# SAMA7G54D1G device description
Architecture: CORTEX-A7; Family: SAMA; Series: SAMA7G
Registers are 32-bit, read-write, reset 0x0 unless marked. A register's access mark holds for its fields unless they carry their own. Offsets are from the block's base; [hi:lo] are bit positions; {n}, {i} and the like mark numbered series; 'fields as' and 'values as' point back to an identical list; <NAME> marks a mode.

## UDDRC (part 3 of 3) — Enhanced Universal DDR-SDRAM Memory Controller
Instances: DDRUMCTL 0xE3800000
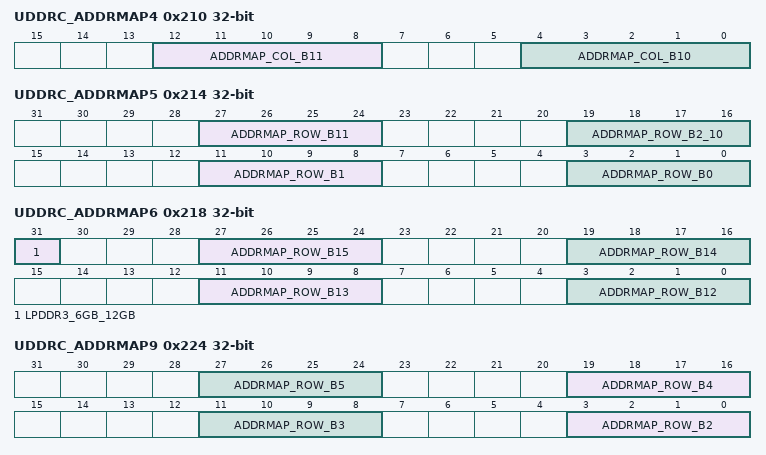
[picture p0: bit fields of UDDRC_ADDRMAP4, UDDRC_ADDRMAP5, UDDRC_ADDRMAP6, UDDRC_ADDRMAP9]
0x210 UDDRC_ADDRMAP4 — Address Map Register 4
  [12:8] ADDRMAP_COL_B11 — - Full bus width mode: Selects the HIF address bit used as column address bit 13 (11 in LPDDR2/LPDDR3 mode). - Half bus width mode: UNUSED. See later in this description for value you need to set to make it unused. - Quarter bus width mode: UNUSED. See later in this description for value you need to set to make it unused. Valid Range: 0 to 7, x, and 31. x indicate a valid value in inline ECC configuration. Internal Base: 11 The selected HIF address bit is determined by adding the internal base to the value of this field. Note: Per JEDEC DDR2/3/mDDR specification, column address bit 10 is reserved for indicating auto-precharge, and hence no source address bit can be mapped to column address bit 10. In LPDDR2/LPDDR3, there is a dedicated bit for auto-precharge in the CA bus and hence column bit 10 is used. In Inline ECC configuration (MEMC_INLINE_ECC=1) and ECC is enabled (ECCCFG0.ecc_mode>0), the highest 3 column address bits must map to the highest 3 valid HIF address bits. If column bit 11 is the highest column address bit, it must map to the highest valid HIF address bit. (x = the highest valid HIF address bit - internal base) If column bit 11 is the second highest column address bit, it must map to the second highest valid HIF address bit. (x = the highest valid HIF address bit - 1 - internal base) If column bit 11 is the third highest column address bit, it must map to the third highest valid HIF address bit. (x = the highest valid HIF address bit - 2 - internal base) If unused, set to 31 and then this column address bit is set to 0. Programming Mode: Static
  [4:0] ADDRMAP_COL_B10 — - Full bus width mode: Selects the HIF address bit used as column address bit 11 (10 in LPDDR2/LPDDR3 mode). - Half bus width mode: Selects the HIF address bit used as column address bit 13 (11 in LPDDR2/LPDDR3 mode). - Quarter bus width mode: UNUSED. See later in this description for value you need to set to make it unused. Valid Range: 0 to 7, x, and 31. x indicate a valid value in inline ECC configuration. Internal Base: 10 The selected HIF address bit is determined by adding the internal base to the value of this field. Note: Per JEDEC DDR2/3/mDDR specification, column address bit 10 is reserved for indicating auto-precharge, and hence no source address bit can be mapped to column address bit 10. In LPDDR2/LPDDR3, there is a dedicated bit for auto-precharge in the CA bus and hence column bit 10 is used. In Inline ECC configuration (MEMC_INLINE_ECC=1) and ECC is enabled (ECCCFG0.ecc_mode>0), the highest 3 column address bits must map to the highest 3 valid HIF address bits. If column bit 10 is the highest column address bit, it must map to the highest valid HIF address bit. (x = the highest valid HIF address bit - internal base) If column bit 10 is the second highest column address bit, it must map to the second highest valid HIF address bit. (x = the highest valid HIF address bit - 1 - internal base) If column bit 10 is the third highest column address bit, it must map to the third highest valid HIF address bit. (x = the highest valid HIF address bit - 2 - internal base) If unused, set to 31 and then this column address bit is set to 0. Programming Mode: Static
0x214 UDDRC_ADDRMAP5 — Address Map Register 5
  [27:24] ADDRMAP_ROW_B11 — Selects the HIF address bit used as row address bit 11. Valid Range: 0 to 11, and 15 Internal Base: 17 The selected HIF address bit is determined by adding the internal base to the value of this field. If unused, set to 15 and then row address bit 11 is set to 0. Programming Mode: Static
  [19:16] ADDRMAP_ROW_B2_10 — Selects the HIF address bits used as row address bits 2 to 10. Valid Range: 0 to 11, and 15 Internal Base: 8 (for row address bit 2), 9 (for row address bit 3), 10 (for row address bit 4) etc increasing to 16 (for row address bit 10) The selected HIF address bit for each of the row address bits is determined by adding the internal base to the value of this field. When set to 15, the values of row address bits 2 to 10 are defined by registers ADDRMAP9, ADDRMAP10, ADDRMAP11. Programming Mode: Static
  [11:8] ADDRMAP_ROW_B1 — Selects the HIF address bits used as row address bit 1. Valid Range: 0 to 11 Internal Base: 7 The selected HIF address bit for each of the row address bits is determined by adding the internal base to the value of this field. Programming Mode: Static
  [3:0] ADDRMAP_ROW_B0 — Selects the HIF address bits used as row address bit 0. Valid Range: 0 to 11 Internal Base: 6 The selected HIF address bit for each of the row address bits is determined by adding the internal base to the value of this field. Programming Mode: Static
0x218 UDDRC_ADDRMAP6 — Address Map Register 6
  [31] LPDDR3_6GB_12GB — Set this to 1 if there is an LPDDR3 SDRAM 6Gb or 12Gb device in use. - 1 - LPDDR3 SDRAM 6Gb/12Gb device in use. Every address having row[14:13]==2'b11 is considered as invalid - 0 - non-LPDDR3 6Gb/12Gb device in use. All addresses are valid Present only in designs configured to support LPDDR3. Programming Mode: Static
  [8n-93:8n-96] ADDRMAP_ROW_B{n} (n=12..15) — Selects the HIF address bit used as row address bit {n}. Valid Range: 0 to 11, and 15 Internal Base: {n+6} The selected HIF address bit is determined by adding the internal base to the value of this field. If unused, set to 15 and then row address bit {n} is set to 0. Programming Mode: Static
0x224 UDDRC_ADDRMAP9 — Address Map Register 9
  [8n-13:8n-16] ADDRMAP_ROW_B{n} (n=2..5) — Selects the HIF address bits used as row address bit {n}. Valid Range: 0 to 11 Internal Base: {n+6} The selected HIF address bit for each of the row address bits is determined by adding the internal base to the value of this field. This register field is used only when ADDRMAP5.addrmap_row_b2_10 is set to value 15. Programming Mode: Static
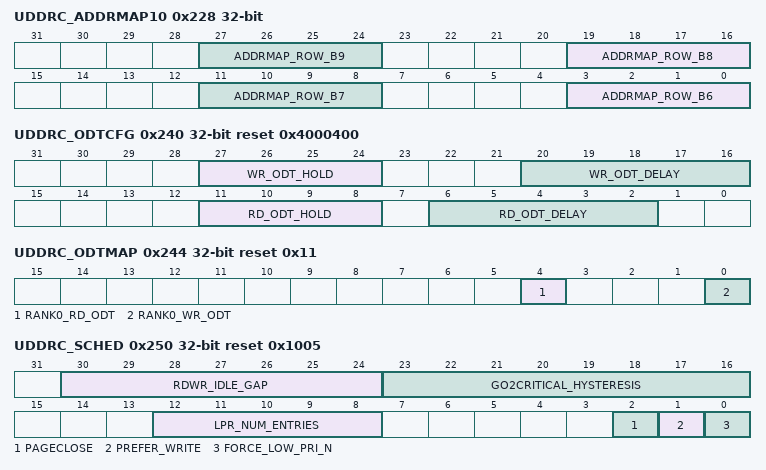
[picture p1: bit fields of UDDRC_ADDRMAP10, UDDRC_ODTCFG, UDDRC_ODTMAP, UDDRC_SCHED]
0x228 UDDRC_ADDRMAP10 — Address Map Register 10
  [8n-45:8n-48] ADDRMAP_ROW_B{n} (n=6..9) — Selects the HIF address bits used as row address bit {n}. Valid Range: 0 to 11 Internal Base: {n+6} The selected HIF address bit for each of the row address bits is determined by adding the internal base to the value of this field. This register field is used only when ADDRMAP5.addrmap_row_b2_10 is set to value 15. Programming Mode: Static
0x22C UDDRC_ADDRMAP11 — Address Map Register 11
  [3:0] ADDRMAP_ROW_B10 — Selects the HIF address bits used as row address bit 10. Valid Range: 0 to 11 Internal Base: 16 The selected HIF address bit for each of the row address bits is determined by adding the internal base to the value of this field. This register field is used only when ADDRMAP5.addrmap_row_b2_10 is set to value 15. Programming Mode: Static
0x240 UDDRC_ODTCFG reset 0x4000400 — ODT Configuration Register
  [27:24] WR_ODT_HOLD — DFI PHY clock cycles to hold ODT for a write command. The minimum supported value is 2. Recommended values: DDR2: - BL8: 0x5 (DDR2-400/533/667), 0x6 (DDR2-800), 0x7 (DDR2-1066) - BL4: 0x3 (DDR2-400/533/667), 0x4 (DDR2-800), 0x5 (DDR2-1066) DDR3: - BL8: 0x6 DDR4: - BL8: 5 + WR_PREAMBLE + CRC_MODE WR_PREAMBLE = 1 (1tCK write preamble), 2 (2tCK write preamble) CRC_MODE = 0 (not CRC mode), 1 (CRC mode) LPDDR3: - BL8: 7 + RU(tODTon(max)/tCK) Unit: DFI PHY clock cycles. Programming Mode: Quasi-dynamic Group 1, Group 4
  [20:16] WR_ODT_DELAY — The delay, in DFI PHY clock cycles, from issuing a write command to setting ODT values associated with that command. ODT setting must remain constant for the entire time that DQS is driven by the uMCTL2. Recommended values: DDR2: - CWL + AL - 3 (DDR2-400/533/667), CWL + AL - 4 (DDR2-800), CWL + AL - 5 (DDR2-1066) If (CWL + AL - 3 < 0), uMCTL2 does not support ODT for write operation. DDR3: - 0x0 DDR4: - DFITMG1.dfi_t_cmd_lat (to adjust for CAL mode) LPDDR3: - WL - 1 - RU(tODTon(max)/tCK)) Unit: DFI PHY clock cycles. Programming Mode: Quasi-dynamic Group 1, Group 4
  [11:8] RD_ODT_HOLD — DFI PHY clock cycles to hold ODT for a read command. The minimum supported value is 2. Recommended values: DDR2: - BL8: 0x6 (not DDR2-1066), 0x7 (DDR2-1066) - BL4: 0x4 (not DDR2-1066), 0x5 (DDR2-1066) DDR3: - BL8 - 0x6 DDR4: - BL8: 5 + RD_PREAMBLE RD_PREAMBLE = 1 (1tCK read preamble), 2 (2tCK read preamble) LPDDR3: - BL8: 5 + RU(tDQSCK(max)/tCK) - RD(tDQSCK(min)/tCK) + RU(tODTon(max)/tCK) Unit: DFI PHY clock cycles. Programming Mode: Quasi-dynamic Group 1, Group 4
  [6:2] RD_ODT_DELAY — The delay, in DFI PHY clock cycles, from issuing a read command to setting ODT values associated with that command. ODT setting must remain constant for the entire time that DQS is driven by the uMCTL2. Recommended values: DDR2: - CL + AL - 4 (not DDR2-1066), CL + AL - 5 (DDR2-1066) If (CL + AL - 4 < 0), uMCTL2 does not support ODT for read operation. DDR3: - CL - CWL DDR4: - CL - CWL - RD_PREAMBLE + WR_PREAMBLE + DFITMG1.dfi_t_cmd_lat (to adjust for CAL mode) WR_PREAMBLE = 1 (1tCK write preamble), 2 (2tCK write preamble) RD_PREAMBLE = 1 (1tCK read preamble), 2 (2tCK read preamble) If (CL - CWL - RD_PREAMBLE + WR_PREAMBLE) < 0, uMCTL2 does not support ODT for read operation. LPDDR3: - RL + RD(tDQSCK(min)/tCK) - 1 - RU(tODTon(max)/tCK) Unit: DFI PHY clock cycles. Programming Mode: Quasi-dynamic Group 1, Group 4
0x244 UDDRC_ODTMAP reset 0x11 — ODT/Rank Map Register
  [4] RANK0_RD_ODT — Indicates which remote ODTs must be turned on during a read from rank 0. Each rank has a remote ODT (in the SDRAM) which can be turned on by setting the appropriate bit here. Rank 0 is controlled by the LSB; rank 1 is controlled by bit next to the LSB, etc. For each rank, set its bit to 1 to enable its ODT. Programming Mode: Static
  [0] RANK0_WR_ODT — Indicates which remote ODTs must be turned on during a write to rank 0. Each rank has a remote ODT (in the SDRAM) which can be turned on by setting the appropriate bit here. Rank 0 is controlled by the LSB; rank 1 is controlled by bit next to the LSB, etc. For each rank, set its bit to 1 to enable its ODT. Programming Mode: Static
0x250 UDDRC_SCHED reset 0x1005 — Scheduler Control Register
  [30:24] RDWR_IDLE_GAP — When the preferred transaction store is empty for these many clock cycles, switch to the alternate transaction store if it is non-empty. The read transaction store (both high and low priority) is the default preferred transaction store and the write transaction store is the alternative store. When prefer write over read is set this is reversed. 0x0 is a legal value for this register. When set to 0x0, the transaction store switching will happen immediately when the switching conditions become true. FOR PERFORMANCE ONLY. Unit: DFI clock cycles. Programming Mode: Static
  [23:16] GO2CRITICAL_HYSTERESIS — UNUSED Programming Mode: Static
  [12:8] LPR_NUM_ENTRIES — Number of entries in the low priority transaction store is this value + 1. (MEMC_NO_OF_ENTRY - (SCHED.lpr_num_entries + 1)) is the number of entries available for the high priority transaction store. Setting this to maximum value allocates all entries to low priority transaction store. Setting this to 0 allocates 1 entry to low priority transaction store and the rest to high priority transaction store. Note: In ECC configurations, the numbers of write and low priority read credits issued is one less than in the non-ECC case. One entry each is reserved in the write and low-priority read CAMs for storing the RMW requests arising out of single bit error correction RMW operation. Programming Mode: Static
  [2] PAGECLOSE — If true, bank is kept open only while there are page hit transactions available in the CAM to that bank. The last read or write command in the CAM with a bank and page hit will be executed with auto-precharge if SCHED1.pageclose_timer=0. Even if this register set to 1 and SCHED1.pageclose_timer is set to 0, explicit precharge (and not auto-precharge) may be issued in some cases where there is a mode switch between Write and Read or between LPR and HPR. The Read and Write commands that are executed as part of the ECC scrub requests are also executed without auto-precharge. If false, the bank remains open until there is a need to close it (to open a different page, or for page timeout or refresh timeout) - also known as open page policy. The open page policy can be overridden by setting the per-command-autopre bit on the HIF interface (hif_cmd_autopre). The pageclose feature provids a midway between Open and Close page policies. FOR PERFORMANCE ONLY. Programming Mode: Quasi-dynamic Group 3
  [1] PREFER_WRITE — If set then the bank selector prefers writes over reads. FOR DEBUG ONLY. Programming Mode: Static
  [0] FORCE_LOW_PRI_N — Active low signal. When asserted ('0'), all incoming transactions are forced to low priority. This implies that all High Priority Read (HPR) and Variable Priority Read commands (VPR) will be treated as Low Priority Read (LPR) commands. On the write side, all Variable Priority Write (VPW) commands will be treated as Normal Priority Write (NPW) commands. Forcing the incoming transactions to low priority implicitly turns off Bypass path for read commands. FOR PERFORMANCE ONLY. Programming Mode: Static
0x254 UDDRC_SCHED1 — Scheduler Control Register 1
  [7:0] PAGECLOSE_TIMER — This field works in conjunction with SCHED.pageclose. It only has meaning if SCHED.pageclose==1. If SCHED.pageclose==1 and pageclose_timer==0, then an auto-precharge may be scheduled for last read or write command in the CAM with a bank and page hit. Note, sometimes an explicit precharge is scheduled instead of the auto-precharge. See SCHED.pageclose for details of when this may happen. If SCHED.pageclose==1 and pageclose_timer>0, then an auto-precharge is not scheduled for last read or write command in the CAM with a bank and page hit. Instead, a timer is started, with pageclose_timer as the initial value. There is a timer on a per bank basis. The timer decrements unless the next read or write in the CAM to a bank is a page hit. It gets reset to pageclose_timer value if the next read or write in the CAM to a bank is a page hit. Once the timer has reached zero, an explcit precharge will be attempted to be scheduled. Unit: DFI clock cycles. Programming Mode: Static
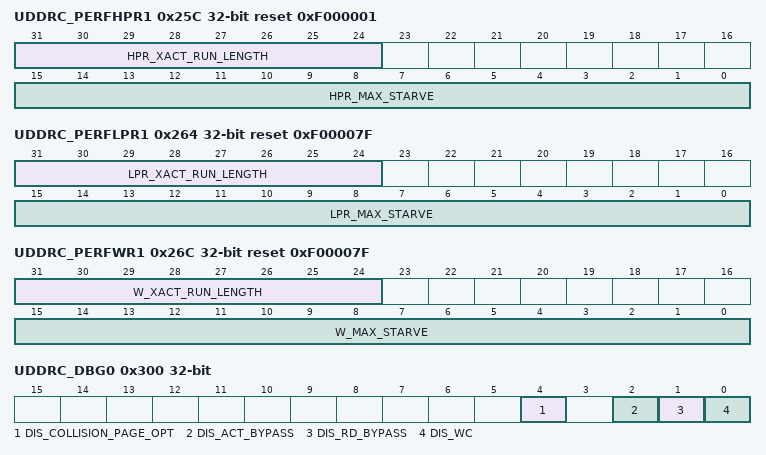
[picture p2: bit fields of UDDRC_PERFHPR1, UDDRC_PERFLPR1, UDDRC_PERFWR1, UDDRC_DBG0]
0x25C UDDRC_PERFHPR1 reset 0xF000001 — High Priority Read CAM Register 1
  [31:24] HPR_XACT_RUN_LENGTH — Number of transactions that are serviced once the HPR queue goes critical is the smaller of: - (a) This number - (b) Number of transactions available. Unit: Transaction. FOR PERFORMANCE ONLY. Programming Mode: Quasi-dynamic Group 3
  [15:0] HPR_MAX_STARVE — Number of DFI clocks that the HPR queue can be starved before it goes critical. The minimum valid functional value for this register is 0x1. Programming it to 0x0 will disable the starvation functionality; during normal operation, this function should not be disabled as it will cause excessive latencies. FOR PERFORMANCE ONLY. Unit: DFI clock cycles. Programming Mode: Quasi-dynamic Group 3
0x264 UDDRC_PERFLPR1 reset 0xF00007F — Low Priority Read CAM Register 1
  [31:24] LPR_XACT_RUN_LENGTH — Number of transactions that are serviced once the LPR queue goes critical is the smaller of: - (a) This number - (b) Number of transactions available. Unit: Transaction. FOR PERFORMANCE ONLY. Programming Mode: Quasi-dynamic Group 3
  [15:0] LPR_MAX_STARVE — Number of DFI clocks that the LPR queue can be starved before it goes critical. The minimum valid functional value for this register is 0x1. Programming it to 0x0 will disable the starvation functionality; during normal operation, this function should not be disabled as it will cause excessive latencies. FOR PERFORMANCE ONLY. Unit: DFI clock cycles. Programming Mode: Quasi-dynamic Group 3
0x26C UDDRC_PERFWR1 reset 0xF00007F — Write CAM Register 1
  [31:24] W_XACT_RUN_LENGTH — Number of transactions that are serviced once the WR queue goes critical is the smaller of: - (a) This number - (b) Number of transactions available. Unit: Transaction. FOR PERFORMANCE ONLY. Programming Mode: Quasi-dynamic Group 3
  [15:0] W_MAX_STARVE — Number of DFI clocks that the WR queue can be starved before it goes critical. The minimum valid functional value for this register is 0x1. Programming it to 0x0 will disable the starvation functionality; during normal operation, this function should not be disabled as it will cause excessive latencies. FOR PERFORMANCE ONLY. Unit: DFI clock cycles. Programming Mode: Quasi-dynamic Group 3
0x300 UDDRC_DBG0 — Debug Register 0
  [4] DIS_COLLISION_PAGE_OPT — When this is set to '0', auto-precharge is disabled for the flushed command in a collision case. Collision cases are write followed by read to same address, read followed by write to same address, or write followed by write to same address with DBG0.dis_wc bit = 1 (where same address comparisons exclude the two address bits representing critical word). FOR DEBUG ONLY. Programming Mode: Static
  [2] DIS_ACT_BYPASS — Only present in designs supporting activate bypass. When 1, disable bypass path for high priority read activates FOR DEBUG ONLY. Programming Mode: Static
  [1] DIS_RD_BYPASS — Only present in designs supporting read bypass. When 1, disable bypass path for high priority read page hits FOR DEBUG ONLY. Programming Mode: Static
  [0] DIS_WC — When 1, disable write combine. FOR DEBUG ONLY Programming Mode: Static
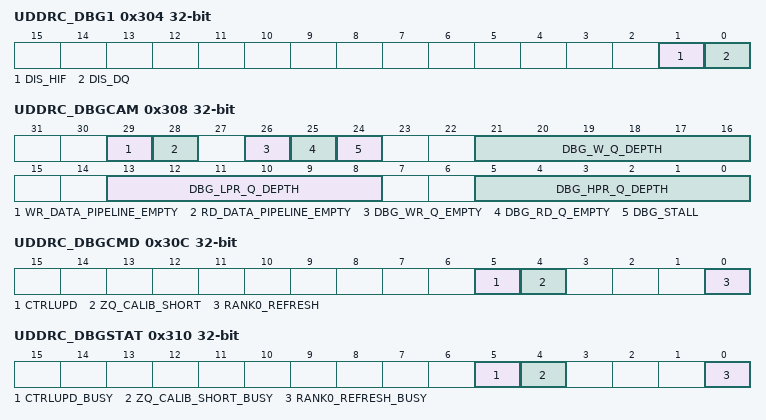
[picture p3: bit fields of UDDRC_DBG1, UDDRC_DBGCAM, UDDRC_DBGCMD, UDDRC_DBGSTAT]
0x304 UDDRC_DBG1 — Debug Register 1
  [1] DIS_HIF — When 1, uMCTL2 asserts the HIF command signal hif_cmd_stall. uMCTL2 will ignore the hif_cmd_valid and all other associated request signals. This bit is intended to be switched on-the-fly. Programming Mode: Dynamic
  [0] DIS_DQ — When 1, uMCTL2 will not de-queue any transactions from the CAM. Bypass is also disabled. All transactions are queued in the CAM. No reads or writes are issued to SDRAM as long as this is asserted. This bit may be used to prevent reads or writes being issued by the uMCTL2, which makes it safe to modify certain register fields associated with reads and writes (see User Guide for details). After setting this bit, it is strongly recommended to poll DBGCAM.wr_data_pipeline_empty and DBGCAM.rd_data_pipeline_empty, before making changes to any registers which affect reads and writes. This will ensure that the relevant logic in the DDRC is idle. This bit is intended to be switched on-the-fly. Programming Mode: Dynamic
0x308 UDDRC_DBGCAM ro — CAM Debug Register
  [29] WR_DATA_PIPELINE_EMPTY — This bit indicates that the write data pipeline on the DFI interface is empty. This register is intended to be polled at least twice after setting DBG1.dis_dq, to ensure that all remaining commands/data have completed. Programming Mode: Dynamic
  [28] RD_DATA_PIPELINE_EMPTY — This bit indicates that the read data pipeline on the DFI interface is empty. This register is intended to be polled at least twice after setting DBG1.dis_dq, to ensure that all remaining commands/data have completed. Programming Mode: Dynamic
  [26] DBG_WR_Q_EMPTY — When 1, all the Write command queues and Write data buffers inside DDRC are empty. This register is to be used for debug purpose. An example use-case scenario: When Controller enters Self-Refresh using the Low-Power entry sequence, Controller is expected to have executed all the commands in its queues and the write and read data drained. Hence this register should be 1 at that time. FOR DEBUG ONLY Programming Mode: Dynamic
  [25] DBG_RD_Q_EMPTY — When 1, all the Read command queues and Read data buffers inside DDRC are empty. This register is to be used for debug purpose. An example use-case scenario: When Controller enters Self-Refresh using the Low-Power entry sequence, Controller is expected to have executed all the commands in its queues and the write and read data drained. Hence this register should be 1 at that time. FOR DEBUG ONLY Programming Mode: Dynamic
  [24] DBG_STALL — Stall FOR DEBUG ONLY Programming Mode: Dynamic
  [21:16] DBG_W_Q_DEPTH — Write queue depth The last entry of WR queue is reserved for ECC SCRUB operation. This entry is not included in the calculation of the queue depth. FOR DEBUG ONLY Programming Mode: Dynamic
  [13:8] DBG_LPR_Q_DEPTH — Low priority read queue depth The last entry of Lpr queue is reserved for ECC SCRUB operation. This entry is not included in the calculation of the queue depth. FOR DEBUG ONLY Programming Mode: Dynamic
  [5:0] DBG_HPR_Q_DEPTH — High priority read queue depth FOR DEBUG ONLY Programming Mode: Dynamic
0x30C UDDRC_DBGCMD — Command Debug Register
  [5] CTRLUPD — Setting this register bit to 1 indicates to the uMCTL2 to issue a dfi_ctrlupd_req to the PHY. When this request is stored in the uMCTL2, the bit is automatically cleared. This operation must only be performed when DFIUPD0.dis_auto_ctrlupd=1. Programming Mode: Dynamic
  [4] ZQ_CALIB_SHORT — Setting this register bit to 1 indicates to the uMCTL2 to issue a ZQCS (ZQ calibration short)/MPC(ZQ calibration) command to the SDRAM. When this request is stored in the uMCTL2, the bit is automatically cleared. This operation can be performed only when ZQCTL0.dis_auto_zq=1. It is recommended NOT to set this register bit if in Init, in Self-Refresh(except LPDDR4) or SR-Powerdown(LPDDR4) or Deep power-down operating modes or Maximum Power Saving Mode. For Self-Refresh(except LPDDR4) or SR-Powerdown(LPDDR4) it will be scheduled after SR(except LPDDR4) or SPRD(LPDDR4) has been exited. For Deep power down and Maximum Power Saving Mode, it will not be scheduled, although DBGSTAT.zq_calib_short_busy will be de-asserted. Programming Mode: Dynamic
  [0] RANK0_REFRESH — Setting this register bit to 1 indicates to the uMCTL2 to issue a refresh to rank 0. Writing to this bit causes DBGSTAT.rank0_refresh_busy to be set. When DBGSTAT.rank0_refresh_busy is cleared, the command has been stored in uMCTL2. For 3DS configuration, refresh is sent to rank index 0. This operation can be performed only when RFSHCTL3.dis_auto_refresh=1. It is recommended NOT to set this register bit if in Init or Deep power-down operating modes or Maximum Power Saving Mode. Programming Mode: Dynamic
0x310 UDDRC_DBGSTAT ro — Status Debug Register
  [5] CTRLUPD_BUSY — SoC core may initiate a ctrlupd operation only if this signal is low. This signal goes high in the clock after the uMCTL2 accepts the ctrlupd request. It goes low when the ctrlupd operation is initiated in the uMCTL2. It is recommended not to perform ctrlupd operations when this signal is high. - 0 - Indicates that the SoC core can initiate a ctrlupd operation - 1 - Indicates that ctrlupd operation has not been initiated yet in the uMCTL2 Programming Mode: Dynamic
  [4] ZQ_CALIB_SHORT_BUSY — SoC core may initiate a ZQCS (ZQ calibration short) operation only if this signal is low. This signal goes high in the clock after the uMCTL2 accepts the ZQCS request. It goes low when the ZQCS operation is initiated in the uMCTL2. It is recommended not to perform ZQCS operations when this signal is high. - 0 - Indicates that the SoC core can initiate a ZQCS operation - 1 - Indicates that ZQCS operation has not been initiated yet in the uMCTL2 Programming Mode: Dynamic
  [0] RANK0_REFRESH_BUSY — SoC core may initiate a rank0_refresh operation (refresh operation to rank 0) only if this signal is low. This signal goes high in the clock after DBGCMD.rank0_refresh is set to one. It goes low when the rank0_refresh operation is stored in the uMCTL2. It is recommended not to perform rank0_refresh operations when this signal is high. - 0 - Indicates that the SoC core can initiate a rank0_refresh operation - 1 - Indicates that rank0_refresh operation has not been stored yet in the uMCTL2 Programming Mode: Dynamic
0x320 UDDRC_SWCTL reset 0x1 — Software Register Programming Control Enable
  [0] SW_DONE — Enable quasi-dynamic register programming outside reset. Program register to 0 to enable quasi-dynamic programming. Set back register to 1 once programming is done. Programming Mode: Dynamic
0x324 UDDRC_SWSTAT ro reset 0x1 — Software Register Programming Control Status
  [0] SW_DONE_ACK — Register programming done. This register is the echo of SWCTL.sw_done. Wait for sw_done value 1 to propagate to sw_done_ack at the end of the programming sequence to ensure that the correct registers values are propagated to the destination clock domains. Programming Mode: Static
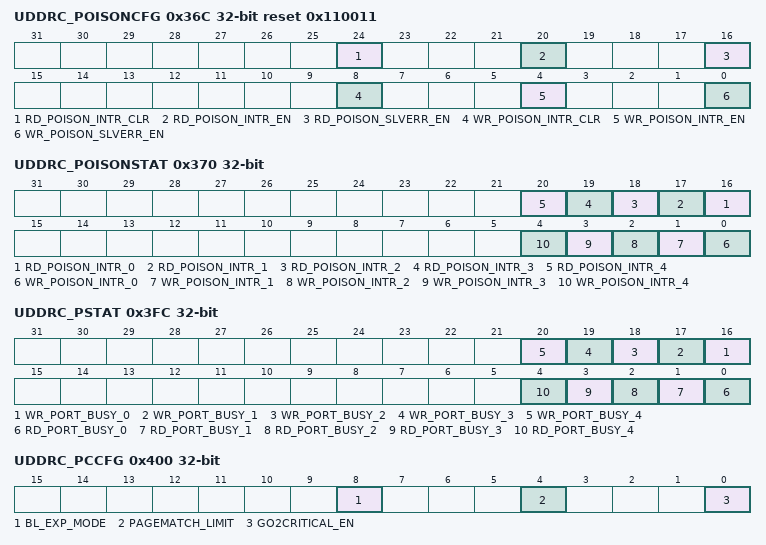
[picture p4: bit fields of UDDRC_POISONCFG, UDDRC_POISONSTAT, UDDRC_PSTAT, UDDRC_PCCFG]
0x36C UDDRC_POISONCFG reset 0x110011 — AXI Poison Configuration Register. Common for all AXI ports
  [24] RD_POISON_INTR_CLR — Interrupt clear for read transaction poisoning. Allow 2/3 clock cycles for correct value to propagate to core logic and clear the interrupts. uMCTL2 automatically clears this bit. Programming Mode: Dynamic
  [20] RD_POISON_INTR_EN — If set to 1, enables interrupts for read transaction poisoning Programming Mode: Dynamic
  [16] RD_POISON_SLVERR_EN — If set to 1, enables SLVERR response for read transaction poisoning Programming Mode: Dynamic
  [8] WR_POISON_INTR_CLR — Interrupt clear for write transaction poisoning. Allow 2/3 clock cycles for correct value to propagate to core logic and clear the interrupts. uMCTL2 automatically clears this bit. Programming Mode: Dynamic
  [4] WR_POISON_INTR_EN — If set to 1, enables interrupts for write transaction poisoning Programming Mode: Dynamic
  [0] WR_POISON_SLVERR_EN — If set to 1, enables SLVERR response for write transaction poisoning Programming Mode: Dynamic
0x370 UDDRC_POISONSTAT ro — AXI Poison Status Register
  [n+16] RD_POISON_INTR_{n} (n=0..4) — Read transaction poisoning error interrupt for port {n}. This register is a APB clock copy (double register synchronizer) of the interrupt asserted when a transaction is poisoned on the corresponding AXI port's read address channel. Bit 0 corresponds to Port 0, and so on. Interrupt is cleared by register rd_poison_intr_clr, then value propagated to APB clock. Programming Mode: Dynamic
  [n] WR_POISON_INTR_{n} (n=0..4) — Write transaction poisoning error interrupt for port {n}. This register is a APB clock copy (double register synchronizer) of the interrupt asserted when a transaction is poisoned on the corresponding AXI port's write address channel. Bit 0 corresponds to Port 0, and so on. Interrupt is cleared by register wr_poison_intr_clr, then value propagated to APB clock. Programming Mode: Dynamic
0x3F0 UDDRC_DERATESTAT ro — Temperature Derate Status Register
  [0] DERATE_TEMP_LIMIT_INTR — Derate temperature interrupt indicating LPDDR2/3/4 SDRAM temperature operating limit is exceeded. This register field is set to 1 when the value read from MR4[2:0] is 3'b000 or 3'b111. Cleared by register DERATECTL.derate_temp_limit_intr_clr. Programming Mode: Static
0x3FC UDDRC_PSTAT ro — Port Status Register
  [n+16] WR_PORT_BUSY_{n} (n=0..4) — Indicates if there are outstanding writes for AXI port {n}. Programming Mode: Dynamic
  [n] RD_PORT_BUSY_{n} (n=0..4) — Indicates if there are outstanding reads for AXI port {n}. Programming Mode: Dynamic
0x400 UDDRC_PCCFG — Port Common Configuration Register
  [8] BL_EXP_MODE — Burst length expansion mode. By default (i.e. bl_exp_mode==0) XPI expands every AXI burst into multiple HIF commands, using the memory burst length as a unit. If set to 1, then XPI will use half of the memory burst length as a unit. This applies to both reads and writes. When MSTR.data_bus_width==00, setting bl_exp_mode to 1 has no effect. This can be used in cases where Partial Writes is enabled (UMCTL2_PARTIAL_WR=1), in order to avoid or minimize t_ccd_l penalty in DDR4 and t_ccd_mw penalty in LPDDR4. Hence, bl_exp_mode=1 is only recommended if DDR4 or LPDDR4. Note that if DBICTL.dm_en=0, functionality is not supported in the following cases: - UMCTL2_PARTIAL_WR=0 - UMCTL2_PARTIAL_WR=1, MSTR.data_bus_width=01, MEMC_BURST_LENGTH=8 and MSTR.burst_rdwr=1000 (LPDDR4 only) - UMCTL2_PARTIAL_WR=1, MSTR.data_bus_width=01, MEMC_BURST_LENGTH=4 and MSTR.burst_rdwr=0100 (DDR4 only), with either MSTR.burstchop=0 or CRCPARCTL1.crc_enable=1 Functionality is also not supported if Data Channel Interleave is enabled Programming Mode: Static
  [4] PAGEMATCH_LIMIT — Page match four limit. If set to 1, limits the number of consecutive same page DDRC transactions that can be granted by the Port Arbiter to four when Page Match feature is enabled. If set to 0, there is no limit imposed on number of consecutive same page DDRC transactions. Programming Mode: Static
  [0] GO2CRITICAL_EN — If set to 1 (enabled), sets co_gs_go2critical_wr and co_gs_go2critical_lpr/co_gs_go2critical_hpr signals going to DDRC based on urgent input (awurgent, arurgent) coming from AXI master. If set to 0 (disabled), co_gs_go2critical_wr and co_gs_go2critical_lpr/co_gs_go2critical_hpr signals at DDRC are driven to 1b'0. For uPCTL2, this register field must be set to 0 Programming Mode: Static
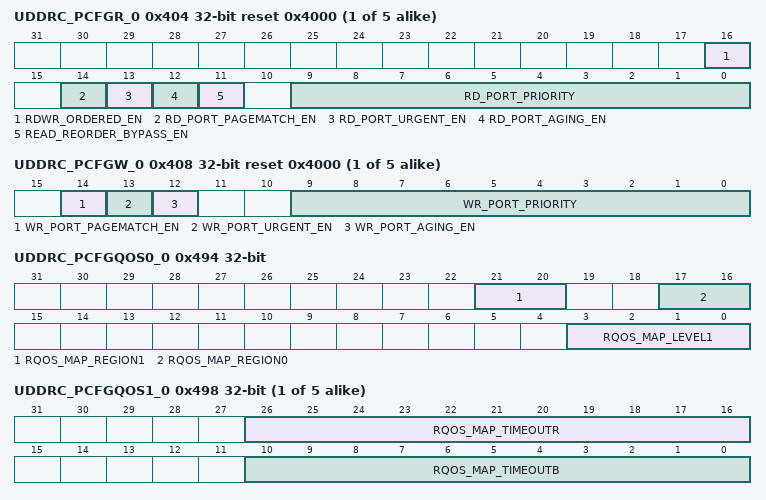
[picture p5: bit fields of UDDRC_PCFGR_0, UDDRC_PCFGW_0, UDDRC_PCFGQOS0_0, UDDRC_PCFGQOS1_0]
{0x404+0xB0*i} UDDRC_PCFGR_{i} reset 0x4000 (i=0..4) — Port n Configuration Read Register
  [16] RDWR_ORDERED_EN — Read/Write AXI transactions acceptance ordering to the same address on a giben port will not be respected when transported to the DFI
  [14] RD_PORT_PAGEMATCH_EN — If set to 1, enables the Page Match feature. If enabled, once a requesting port is granted, the port is continued to be granted if the following immediate commands are to the same memory page (same bank and same row). See also related PCCFG.pagematch_limit register. Programming Mode: Static
  [13] RD_PORT_URGENT_EN — If set to 1, enables the AXI urgent sideband signal (arurgent). When enabled and arurgent is asserted by the master, that port becomes the highest priority and co_gs_go2critical_lpr/co_gs_go2critical_hpr signal to DDRC is asserted if enabled in PCCFG.go2critical_en register. Note that arurgent signal can be asserted anytime and as long as required which is independent of address handshaking (it is not associated with any particular command). Programming Mode: Static
  [12] RD_PORT_AGING_EN — If set to 1, enables aging function for the read channel of the port. Programming Mode: Static
  [11] READ_REORDER_BYPASS_EN — All transactions can be reordered even if ID not found in any RBB channel
  [9:0] RD_PORT_PRIORITY — Determines the initial load value of read aging counters. These counters will be parallel loaded after reset, or after each grant to the corresponding port. The aging counters down-count every clock cycle where the port is requesting but not granted. The higher significant 5-bits of the read aging counter sets the priority of the read channel of a given port. Port's priority will increase as the higher significant 5-bits of the counter starts to decrease. When the aging counter becomes 0, the corresponding port channel will have the highest priority level (timeout condition - Priority0). For multi-port configurations, the aging counters cannot be used to set port priorities when external dynamic priority inputs (arqos) are enabled (timeout is still applicable). For single port configurations, the aging counters are only used when they timeout (become 0) to force read-write direction switching. In this case, external dynamic priority input, arqos (for reads only) can still be used to set the DDRC read priority (2 priority levels: low priority read - LPR, high priority read - HPR) on a command by command basis. Note: The two LSBs of this register field are tied internally to 2'b00. Programming Mode: Static
{0x408+0xB0*i} UDDRC_PCFGW_{i} reset 0x4000 (i=0..4) — Port n Configuration Write Register
  [14] WR_PORT_PAGEMATCH_EN — If set to 1, enables the Page Match feature. If enabled, once a requesting port is granted, the port is continued to be granted if the following immediate commands are to the same memory page (same bank and same row). See also related PCCFG.pagematch_limit register. Programming Mode: Static
  [13] WR_PORT_URGENT_EN — If set to 1, enables the AXI urgent sideband signal (awurgent). When enabled and awurgent is asserted by the master, that port becomes the highest priority and co_gs_go2critical_wr signal to DDRC is asserted if enabled in PCCFG.go2critical_en register. Note that awurgent signal can be asserted anytime and as long as required which is independent of address handshaking (it is not associated with any particular command). Programming Mode: Static
  [12] WR_PORT_AGING_EN — If set to 1, enables aging function for the write channel of the port. Programming Mode: Static
  [9:0] WR_PORT_PRIORITY — Determines the initial load value of write aging counters. These counters will be parallel loaded after reset, or after each grant to the corresponding port. The aging counters down-count every clock cycle where the port is requesting but not granted. The higher significant 5-bits of the write aging counter sets the initial priority of the write channel of a given port. Port's priority will increase as the higher significant 5-bits of the counter starts to decrease. When the aging counter becomes 0, the corresponding port channel will have the highest priority level. For multi-port configurations, the aging counters cannot be used to set port priorities when external dynamic priority inputs (awqos) are enabled (timeout is still applicable). For single port configurations, the aging counters are only used when they timeout (become 0) to force read-write direction switching. Note: The two LSBs of this register field are tied internally to 2'b00. Programming Mode: Static
{0x490+0xB0*i} UDDRC_PCTRL_{i} (i=0..4) — Port n Control Register
  [0] PORT_EN — Enables AXI port n. Programming Mode: Dynamic
0x494 UDDRC_PCFGQOS0_0 — Port n Read QoS Configuration Register 0
  [21:20] RQOS_MAP_REGION1 — This bitfield indicates the traffic class of region 1. Valid values are: - 0 : LPR - 1: VPR - 2: HPR For dual address queue configurations, region1 maps to the blue address queue. In this case, valid values are - 0: LPR - 1: VPR only When VPR support is disabled (UMCTL2_VPR_EN = 0) and traffic class of region 1 is set to 1 (VPR), VPR traffic is aliased to LPR traffic. Programming Mode: Quasi-dynamic Group 3
  [17:16] RQOS_MAP_REGION0 — This bitfield indicates the traffic class of region 0. Valid values are: - 0: LPR - 1: VPR - 2: HPR For dual address queue configurations, region 0 maps to the blue address queue. In this case, valid values are: 0: LPR and 1: VPR only. When VPR support is disabled (UMCTL2_VPR_EN = 0) and traffic class of region0 is set to 1 (VPR), VPR traffic is aliased to LPR traffic. Programming Mode: Quasi-dynamic Group 3
  [3:0] RQOS_MAP_LEVEL1 — Separation level1 indicating the end of region0 mapping; start of region0 is 0. Possible values for level1 are 0 to 13 (for dual RAQ) or 0 to 14 (for single RAQ) which corresponds to arqos. Note that for PA, arqos values are used directly as port priorities, where the higher the value corresponds to higher port priority. All of the map_level* registers must be set to distinct values. Programming Mode: Quasi-dynamic Group 3
{0x498+0xB0*i} UDDRC_PCFGQOS1_{i} (i=0..4) — Port n Read QoS Configuration Register 1
  [26:16] RQOS_MAP_TIMEOUTR — Specifies the timeout value for transactions mapped to the red address queue. Programming Mode: Quasi-dynamic Group 3
  [10:0] RQOS_MAP_TIMEOUTB — Specifies the timeout value for transactions mapped to the blue address queue. Programming Mode: Quasi-dynamic Group 3
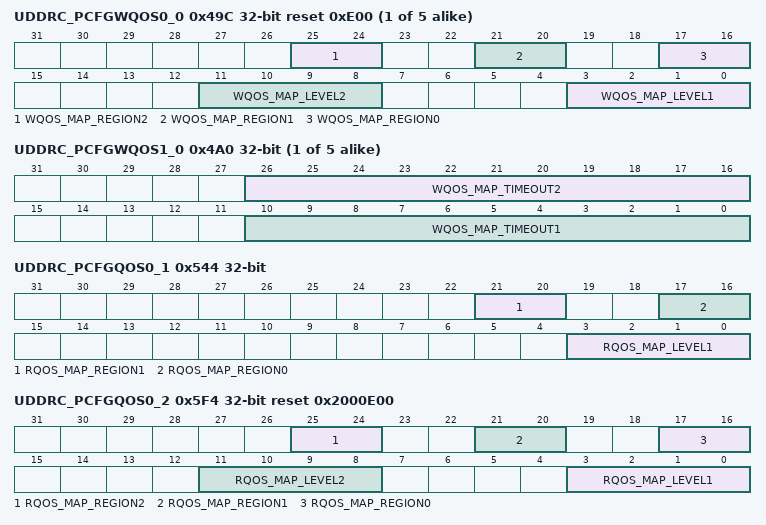
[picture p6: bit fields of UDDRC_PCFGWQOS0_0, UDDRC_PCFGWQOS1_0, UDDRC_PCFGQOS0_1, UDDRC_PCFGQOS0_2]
{0x49C+0xB0*i} UDDRC_PCFGWQOS0_{i} reset 0xE00 (i=0..4) — Port n Write QoS Configuration Register 0
  [25:24] WQOS_MAP_REGION2 — This bitfield indicates the traffic class of region 2. Valid values are: 0: NPW, 1: VPW. When VPW support is disabled (UMCTL2_VPW_EN = 0) and traffic class of region 2 is set to 1 (VPW), VPW traffic is aliased to NPW traffic. Programming Mode: Quasi-dynamic Group 3
  [21:20] WQOS_MAP_REGION1 — This bitfield indicates the traffic class of region 1. Valid values are: 0: NPW, 1: VPW. When VPW support is disabled (UMCTL2_VPW_EN = 0) and traffic class of region 1 is set to 1 (VPW), VPW traffic is aliased to NPW traffic. Programming Mode: Quasi-dynamic Group 3
  [17:16] WQOS_MAP_REGION0 — This bitfield indicates the traffic class of region 0. Valid values are: 0: NPW, 1: VPW. When VPW support is disabled (UMCTL2_VPW_EN = 0) and traffic class of region 0 is set to 1 (VPW), VPW traffic is aliased to NPW traffic. Programming Mode: Quasi-dynamic Group 3
  [11:8] WQOS_MAP_LEVEL2 — Separation level2 indicating the end of region1 mapping; start of region1 is (level1 + 1). Possible values for level2 are (level1 + 1) to 14 which corresponds to awqos. Region2 starts from (level2 + 1) up to 15. Note that for PA, awqos values are used directly as port priorities, where the higher the value corresponds to higher port priority. All of the map_level* registers must be set to distinct values. Programming Mode: Quasi-dynamic Group 3
  [3:0] WQOS_MAP_LEVEL1 — Separation level indicating the end of region0 mapping; start of region0 is 0. Possible values for level1 are 0 to 13 which corresponds to awqos. Note that for PA, awqos values are used directly as port priorities, where the higher the value corresponds to higher port priority. All of the map_level* registers must be set to distinct values. Programming Mode: Quasi-dynamic Group 3
{0x4A0+0xB0*i} UDDRC_PCFGWQOS1_{i} (i=0..4) — Port n Write QoS Configuration Register 1
  [26:16] WQOS_MAP_TIMEOUT2 — Specifies the timeout value for write transactions in region 2. Programming Mode: Quasi-dynamic Group 3
  [10:0] WQOS_MAP_TIMEOUT1 — Specifies the timeout value for write transactions in region 0 and 1. Programming Mode: Quasi-dynamic Group 3
0x544 UDDRC_PCFGQOS0_1 — Port n Read QoS Configuration Register 0
  fields as UDDRC_PCFGQOS0_0
0x5F4 UDDRC_PCFGQOS0_2 reset 0x2000E00 — Port n Read QoS Configuration Register 0
  [25:24] RQOS_MAP_REGION2 — This bitfield indicates the traffic class of region2. For dual address queue configurations, region2 maps to the red address queue. Valid values are 1: VPR and 2: HPR only. When VPR support is disabled (UMCTL2_VPR_EN = 0) and traffic class of region2 is set to 1 (VPR), VPR traffic is aliased to LPR traffic. Programming Mode: Quasi-dynamic Group 3
  [21:20] RQOS_MAP_REGION1 — This bitfield indicates the traffic class of region 1. Valid values are: - 0 : LPR - 1: VPR - 2: HPR For dual address queue configurations, region1 maps to the blue address queue. In this case, valid values are - 0: LPR - 1: VPR only When VPR support is disabled (UMCTL2_VPR_EN = 0) and traffic class of region 1 is set to 1 (VPR), VPR traffic is aliased to LPR traffic. Programming Mode: Quasi-dynamic Group 3
  [17:16] RQOS_MAP_REGION0 — This bitfield indicates the traffic class of region 0. Valid values are: - 0: LPR - 1: VPR - 2: HPR For dual address queue configurations, region 0 maps to the blue address queue. In this case, valid values are: 0: LPR and 1: VPR only. When VPR support is disabled (UMCTL2_VPR_EN = 0) and traffic class of region0 is set to 1 (VPR), VPR traffic is aliased to LPR traffic. Programming Mode: Quasi-dynamic Group 3
  [11:8] RQOS_MAP_LEVEL2 — Separation level2 indicating the end of region1 mapping; start of region1 is (level1 + 1). Possible values for level2 are (level1 + 1) to 14 which corresponds to arqos. Region2 starts from (level2 + 1) up to 15. Note that for PA, arqos values are used directly as port priorities, where the higher the value corresponds to higher port priority. All of the map_level* registers must be set to distinct values. Programming Mode: Quasi-dynamic Group 3
  [3:0] RQOS_MAP_LEVEL1 — Separation level1 indicating the end of region0 mapping; start of region0 is 0. Possible values for level1 are 0 to 13 (for dual RAQ) or 0 to 14 (for single RAQ) which corresponds to arqos. Note that for PA, arqos values are used directly as port priorities, where the higher the value corresponds to higher port priority. All of the map_level* registers must be set to distinct values. Programming Mode: Quasi-dynamic Group 3
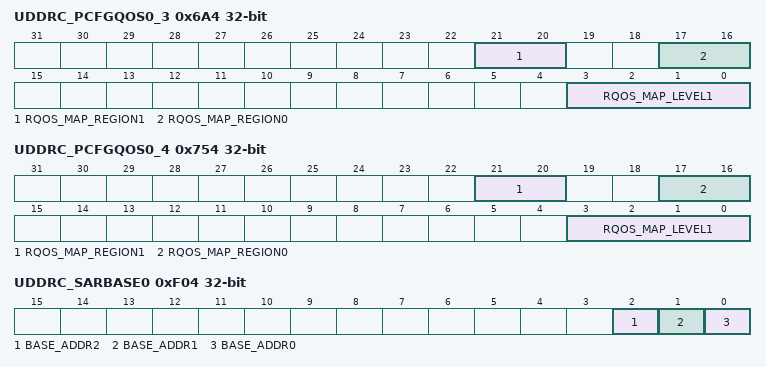
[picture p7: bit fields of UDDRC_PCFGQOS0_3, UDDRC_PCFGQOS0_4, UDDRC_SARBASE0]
0x6A4 UDDRC_PCFGQOS0_3 — Port n Read QoS Configuration Register 0
  fields as UDDRC_PCFGQOS0_0
0x754 UDDRC_PCFGQOS0_4 — Port n Read QoS Configuration Register 0
  fields as UDDRC_PCFGQOS0_0
0xF04 UDDRC_SARBASE0 — SAR Base Address Register n
  [2] BASE_ADDR2 — Base address for address region n specified as awaddr[UMCTL2_A_ADDRW-1:x] and araddr[UMCTL2_A_ADDRW-1:x] where 2 is determined by the minimum block size parameter UMCTL2_SARMINSIZE: (x=log2(block size)). Programming Mode: Static
  [1] BASE_ADDR1 — Base address for address region n specified as awaddr[UMCTL2_A_ADDRW-1:x] and araddr[UMCTL2_A_ADDRW-1:x] where 1 is determined by the minimum block size parameter UMCTL2_SARMINSIZE: (x=log2(block size)). Programming Mode: Static
  [0] BASE_ADDR0 — Base address for address region n specified as awaddr[UMCTL2_A_ADDRW-1:x] and araddr[UMCTL2_A_ADDRW-1:x] where 0 is determined by the minimum block size parameter UMCTL2_SARMINSIZE: (x=log2(block size)). Programming Mode: Static
0xF08 UDDRC_SARSIZE0 — SAR Size Register n
  [7:0] NBLOCKS — Number of blocks for address region n. This register determines the total size of the region in multiples of minimum block size as specified by the hardware parameter UMCTL2_SARMINSIZE. The register value is encoded as number of blocks = nblocks + 1. For example, if register is programmed to 0, region will have 1 block. Programming Mode: Static
0xFF0 UDDRC_VER_NUMBER ro reset 0x3334302A — Version Number Register
  [31:0] VER_NUMBER — Indicates the Device Version Number value. Programming Mode: Static
0xFF4 UDDRC_VER_TYPE ro reset 0x67612A2A — Version Type Register
  [31:0] VER_TYPE — Indicates the Device Version Type value. Programming Mode: Static
